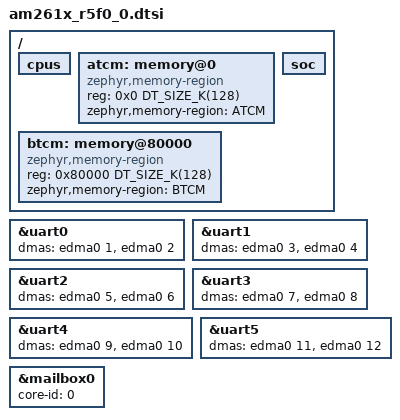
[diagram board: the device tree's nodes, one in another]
/*
 * Copyright (c) 2025 Texas Instruments Incorporated
 *
 * SPDX-License-Identifier: Apache-2.0
 */

#include "am261x.dtsi"
/ {

	cpus {
		/delete-node/ cpu1;
	};

	atcm: memory@0 {
		device_type = "memory";
		compatible = "zephyr,memory-region";
		reg = <0x0 DT_SIZE_K(128)>;
		zephyr,memory-region = "ATCM";
	};

	btcm: memory@80000 {
		device_type = "memory";
		compatible = "zephyr,memory-region";
		reg = <0x80000 DT_SIZE_K(128)>;
		zephyr,memory-region = "BTCM";
	};

    soc {
        /delete-node/ gpio1;
	};
};

&uart0 {
	dmas = <&edma0 1>, <&edma0 2>;
	dma-names = "tx", "rx";
};

&uart1 {
	dmas = <&edma0 3>, <&edma0 4>;
	dma-names = "tx", "rx";
};

&uart2 {
	dmas = <&edma0 5>, <&edma0 6>;
	dma-names = "tx", "rx";
};

&uart3 {
	dmas = <&edma0 7>, <&edma0 8>;
	dma-names = "tx", "rx";
};

&uart4 {
	dmas = <&edma0 9>, <&edma0 10>;
	dma-names = "tx", "rx";
};

&uart5 {
	dmas = <&edma0 11>, <&edma0 12>;
	dma-names = "tx", "rx";
};

&mailbox0 {
	core-id = <0>;
};

